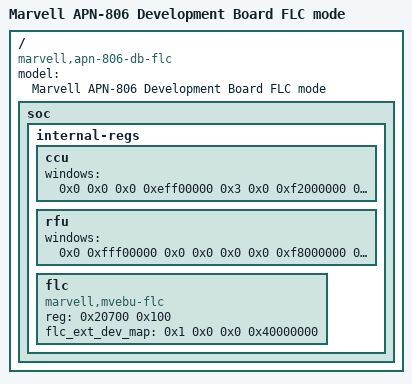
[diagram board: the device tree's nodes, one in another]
/*
 * ***************************************************************************
 * Copyright (C) 2015 Marvell International Ltd.
 * ***************************************************************************
 * This program is free software: you can redistribute it and/or modify it
 * under the terms of the GNU General Public License as published by the Free
 * Software Foundation, either version 2 of the License, or any later version.
 *
 * This program is distributed in the hope that it will be useful,
 * but WITHOUT ANY WARRANTY; without even the implied warranty of
 * MERCHANTABILITY or FITNESS FOR A PARTICULAR PURPOSE.  See the
 * GNU General Public License for more details.
 *
 * You should have received a copy of the GNU General Public License
 * along with this program.  If not, see <http://www.gnu.org/licenses/>.
 * ***************************************************************************
 */

/dts-v1/;

#include "apn-806-db.dtsi"

/ {
	model = "Marvell APN-806 Development Board FLC mode";
	compatible = "marvell,apn-806-db-flc", "marvell,apn-806-db", "marvell,apn-806";

	soc {
		internal-regs {

			ccu {
				windows = <0x0 0x0  0x0 0xeff00000 0x3 /* DRAM window */
				0x0 0xf2000000 0x0 0xe000000 0x00 /* IO window */>;
			};

			rfu {
				windows = <
					0x0 0xfff00000 0x0 0x0 0x0 /*BootROM */
					0x0 0xf8000000 0x0 0x1100000 0x2 /* SPI */
					0x0 0xfe000000 0x0 0x1f00000 0x05 /* PCIe window 31Mb for PCIe port*/
					0x0 0xffe00000 0x0 0x100000 0x03 /* PCI-REG window 64Kb for PCIe-reg*/>;
			};

			flc {
				compatible = "marvell,mvebu-flc";
				reg = <0x20700 0x100>;
				flc_ext_dev_map = <0x1 0x0 0x0 0x40000000>;
			};

		};
	};
};

